# $root: IP-XACT component
VLNV example.org:mylibrary:$root:1.0

## Address spaces and blocks
tr_mmap.tr: base 'h0, range 'h8ff44, width 32

## Registers
Registers are 32-bit, read-write, reset 0x0 unless marked. A register's access mark holds for its fields unless they carry their own. Offsets are from the block's base; lines under a group give offsets from that group; [hi:lo] are bit positions; {n}, {i} and the like mark numbered series; 'fields as' and 'values as' point back to an identical list; <NAME> marks a mode.

## tr_mmap.tr
Base 0x00000000
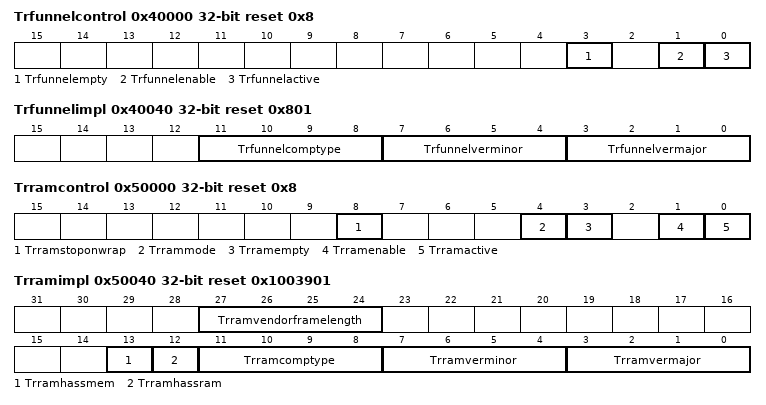
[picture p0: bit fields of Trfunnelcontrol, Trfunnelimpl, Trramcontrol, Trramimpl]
0x40000 Trfunnelcontrol access per field reset 0x8
  [3] Trfunnelempty ro, [1] Trfunnelenable rw, [0] Trfunnelactive rw
0x40040 Trfunnelimpl ro reset 0x801
  [11:8] Trfunnelcomptype
  [7:4] Trfunnelverminor — e
  [3:0] Trfunnelvermajor
0x40080 Trfunneldisinput
  [15:0] Trfunneldisinput — Bits 7:0 are reserved for N-trace srcs and 15:8 for Dst sources
0x50000 Trramcontrol access per field reset 0x8
  [8] Trramstoponwrap rw, [4] Trrammode rw, [3] Trramempty ro, [1] Trramenable rw, [0] Trramactive rw
0x50040 Trramimpl access per field reset 0x1003901
  [27:24] Trramvendorframelength rw, [13] Trramhassmem ro, [12] Trramhassram ro, [11:8] Trramcomptype ro, [7:4] Trramverminor ro, [3:0] Trramvermajor ro
0x50100 Trramstartlow access per field
  [31:2] Trramstartlow rw
0x50140 Trramstarthigh
0x50180 Trramlimitlow access per field reset 0x8000
  [31:2] Trramlimitlow rw
0x501C0 Trramlimithigh
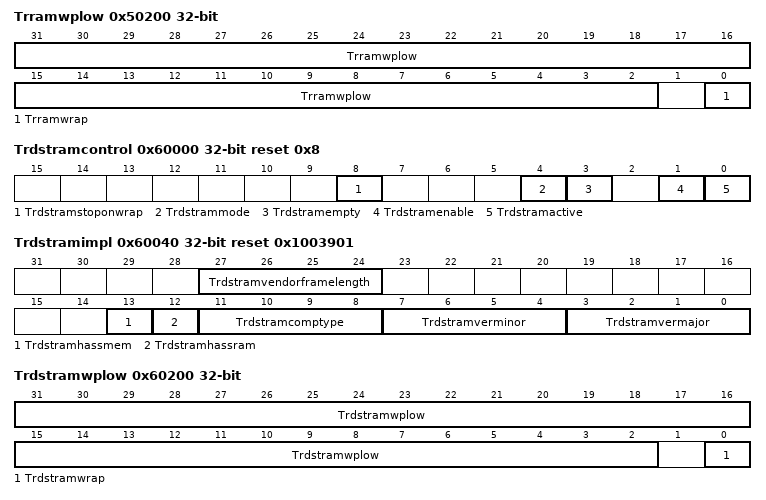
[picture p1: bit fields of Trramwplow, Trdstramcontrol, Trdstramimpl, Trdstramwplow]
0x50200 Trramwplow access per field
  [31:2] Trramwplow rw, [0] Trramwrap ro
0x50240 Trramwphigh
0x50280 Trramrplow access per field
  [31:2] Trramrplow rw
0x502C0 Trramrphigh
0x50400 Trramdata ro
0x5E000 Trcustomramsmemlimitlow access per field reset 0x4000
  [31:2] Trcustomramsmemlimitlow rw
0x60000 Trdstramcontrol access per field reset 0x8
  [8] Trdstramstoponwrap rw, [4] Trdstrammode rw, [3] Trdstramempty ro, [1] Trdstramenable rw, [0] Trdstramactive rw
0x60040 Trdstramimpl access per field reset 0x1003901
  [27:24] Trdstramvendorframelength rw, [13] Trdstramhassmem ro, [12] Trdstramhassram ro, [11:8] Trdstramcomptype ro, [7:4] Trdstramverminor ro, [3:0] Trdstramvermajor ro
0x60100 Trdstramstartlow access per field
  [31:2] Trdstramstartlow rw
0x60140 Trdstramstarthigh
0x60180 Trdstramlimitlow access per field
  [31:2] Trdstramlimitlow rw
0x601C0 Trdstramlimithigh
0x60200 Trdstramwplow access per field
  [31:2] Trdstramwplow rw, [0] Trdstramwrap ro
0x60240 Trdstramwphigh
0x60280 Trdstramrplow access per field
  [31:2] Trdstramrplow rw
0x602C0 Trdstramrphigh
0x60400 Trdstramdata ro
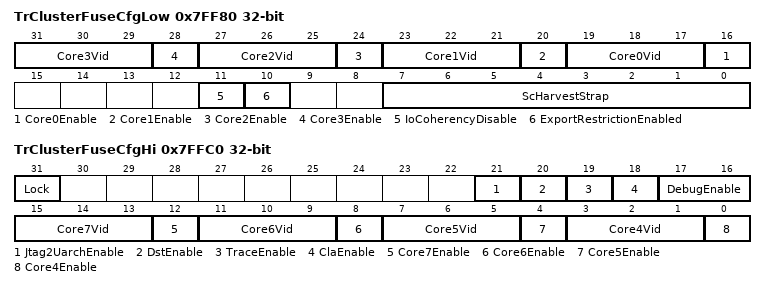
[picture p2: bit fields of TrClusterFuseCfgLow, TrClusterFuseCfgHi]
0x7FF80 TrClusterFuseCfgLow
  [4n+19:4n+17] Core{n}Vid (n=0..3) — Physical Core{n} vid
  [4n+16] Core{n}Enable (n=0..3) — Physical Core{n} availability
  [11] IoCoherencyDisable — IO coherency disable bit used in sharedcache bridge: If 1: ACB will respond with DECERR when it receives a request outside the SC/SCB domains (MMR or SP)
  [10] ExportRestrictionEnabled — Use reduced FP throughput to comply with export restriction
  [7:0] ScHarvestStrap — 1 bit / 4 ways (total 8 bit /32 ways possible) 1: enable 0: disabled
0x7FFC0 TrClusterFuseCfgHi
  [31] Lock — Lock bit
  [21] Jtag2UarchEnable — JTAG to AXI enable
  [20] DstEnable
  [19] TraceEnable
  [18] ClaEnable
  [17:16] DebugEnable — Debug enable. debug_enable[1]: AXI access to DM; debug_enable[0]: DM
  [15:13] Core7Vid — Physical core7 vid
  [12] Core7Enable — Physical core7 availability
  [11:9] Core6Vid — Physical Core6 vid
  [8] Core6Enable — Physical Core6 availability
  [7:5] Core5Vid — Physical Core5 vid
  [4] Core5Enable — Physical Core5 availability
  [3:1] Core4Vid — Physical Core4 vid
  [0] Core4Enable — Physical Core4 availability
0x8FE80 TrScratchLo — Additional scratch register for DV and potential ECO usage
  [31:0] Data
0x8FEC0 TrScratchHi — Additional scratch register for DV and potential ECO usage
  [31:0] Data
0x8FF00 TrScratchpadLo reset 0xEFEFEFEF — Scratchpad register for DV
  [31:0] Data
0x8FF40 TrScratchpadHi reset 0xEFEFEFEF — Scratchpad register for DV
  [31:0] Data
